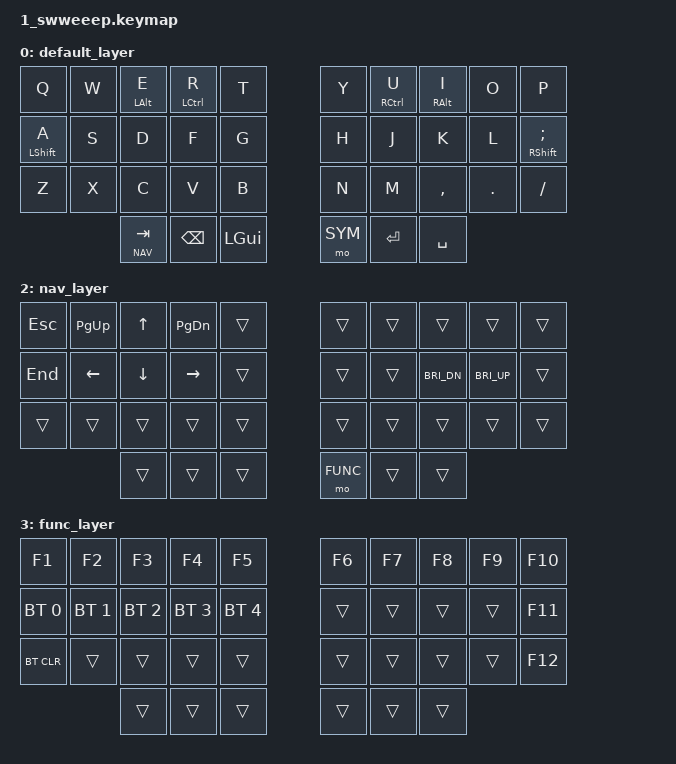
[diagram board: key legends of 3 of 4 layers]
#include <behaviors.dtsi>
#include <dt-bindings/zmk/keys.h>
#include <dt-bindings/zmk/bt.h>

// Layer Defines
#define DEFAULT 0
#define SYM     1
#define NAV     2
#define FUNC    3

/ {
    // Custom behaviors to fine-tune hold-tap settings for specific use cases.
    // `hm` uses 'tap-preferred' for home row mods, and `lt_nav_tab` is isolated for independent thumb key tuning.
    behaviors {
        // Hold-Tap for Home Row Mods (Ctrl, Alt, Shift)
        hm: homerow_mods {
            compatible = "zmk,behavior-hold-tap";
            label = "HOMEROW_MODS";
            #binding-cells = <2>;
            tapping-term-ms = <200>;
            quick-tap-ms = <175>;
            flavor = "tap-preferred";
            bindings = <&kp>, <&kp>;
        };

        // Layer-Tap for Thumb Keys
        lt_nav_tab: layer_tap_nav_tab {
            compatible = "zmk,behavior-hold-tap";
            label = "LAYER_TAP_NAV_TAB";
            #binding-cells = <2>;
            tapping-term-ms = <200>;
            flavor = "hold-preferred";
            bindings = <&mo>, <&kp>;
        };
    };

    combos {
        compatible = "zmk,combos";

        // Bootloader: Press all 6 thumb keys and Q
        combo_bootloader {
            timeout-ms = <50>;
            key-positions = <0 30 31 32 33 34 35>;
            bindings = <&bootloader>;
        };

        // Reset: Press all 6 thumb keys and R
        combo_reset {
            timeout-ms = <50>;
            key-positions = <3 30 31 32 33 34 35>;
            bindings = <&sys_reset>;
        };
    };

    keymap {
        compatible = "zmk,keymap";

        default_layer {
            bindings = <
&kp Q       &kp W       &hm LALT E    &hm LCTL R    &kp T         &kp Y       &hm RCTL U    &hm RALT I    &kp O       &kp P
&hm LSHFT A &kp S       &kp D         &kp F         &kp G         &kp H       &kp J         &kp K         &kp L       &hm RSHFT SEMI
&kp Z       &kp X       &kp C         &kp V         &kp B         &kp N       &kp M         &kp COMMA     &kp DOT     &kp SLASH
                                    &lt_nav_tab NAV TAB &kp BSPC      &kp LGUI      &mo SYM       &kp RET       &kp SPACE
            >;
        };

        sym_layer {
            bindings = <
&kp N1     &kp N2     &kp N3        &kp N4        &kp N5        &kp N6        &kp N7        &kp N8        &kp N9        &kp N0
&kp LSHFT  &trans     &trans        &trans        &trans        &trans        &trans        &kp LBKT      &kp RBKT      &kp BSLH 
&kp GRAVE  &trans     &trans        &trans        &trans        &trans        &trans        &kp MINUS     &kp EQUAL     &kp SQT
                                    &trans        &trans        &trans        &trans        &trans        &trans        &trans
            >;
        };

        nav_layer {
            bindings = <
&kp ESC    &kp PG_UP  &kp UP        &kp PG_DN     &trans        &trans       &trans        &trans        &trans     &trans
&kp END    &kp LEFT   &kp DOWN      &kp RIGHT     &trans        &trans       &trans        &kp C_BRI_DN  &kp C_BRI_UP &trans
&trans     &trans     &trans        &trans        &trans        &trans       &trans        &trans        &trans     &trans
                                    &trans        &trans        &trans       &mo FUNC      &trans        &trans
            >;
        };

        func_layer {
            bindings = <
&kp F1     &kp F2     &kp F3        &kp F4        &kp F5        &kp F6     &kp F7        &kp F8        &kp F9     &kp F10
&bt BT_SEL 0 &bt BT_SEL 1 &bt BT_SEL 2 &bt BT_SEL 3 &bt BT_SEL 4 &trans     &trans        &trans        &trans     &kp F11
&bt BT_CLR &trans     &trans        &trans        &trans        &trans     &trans        &trans        &trans     &kp F12
                                    &trans        &trans        &trans     &trans        &trans        &trans
            >;
        };
    };
};
